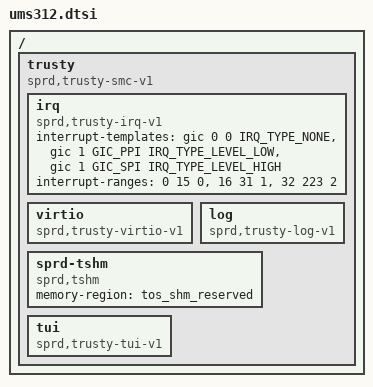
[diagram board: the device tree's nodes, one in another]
// SPDX-License-Identifier: (GPL-2.0+ OR MIT)
/*
 * Unisoc TRUSTY dts file
 *
 * Copyright (C) 2020, Unisoc Inc.
 *
 */

/ {
	trusty {
		compatible = "sprd,trusty-smc-v1";

		irq {
			compatible = "sprd,trusty-irq-v1";
			interrupt-templates = <&gic 0 0 IRQ_TYPE_NONE>,
					      <&gic 1 GIC_PPI IRQ_TYPE_LEVEL_LOW>,
					      <&gic 1 GIC_SPI IRQ_TYPE_LEVEL_HIGH>;
			interrupt-ranges = < 0  15 0>,
					   <16  31 1>,
					   <32 223 2>;
		};

		virtio {
			compatible = "sprd,trusty-virtio-v1";
		};

		log {
			compatible = "sprd,trusty-log-v1";
		};

		sprd-tshm {
			compatible = "sprd,tshm";
			memory-region = <&tos_shm_reserved>;
		};

		tui {
			compatible = "sprd,trusty-tui-v1";
		};
	};
};
